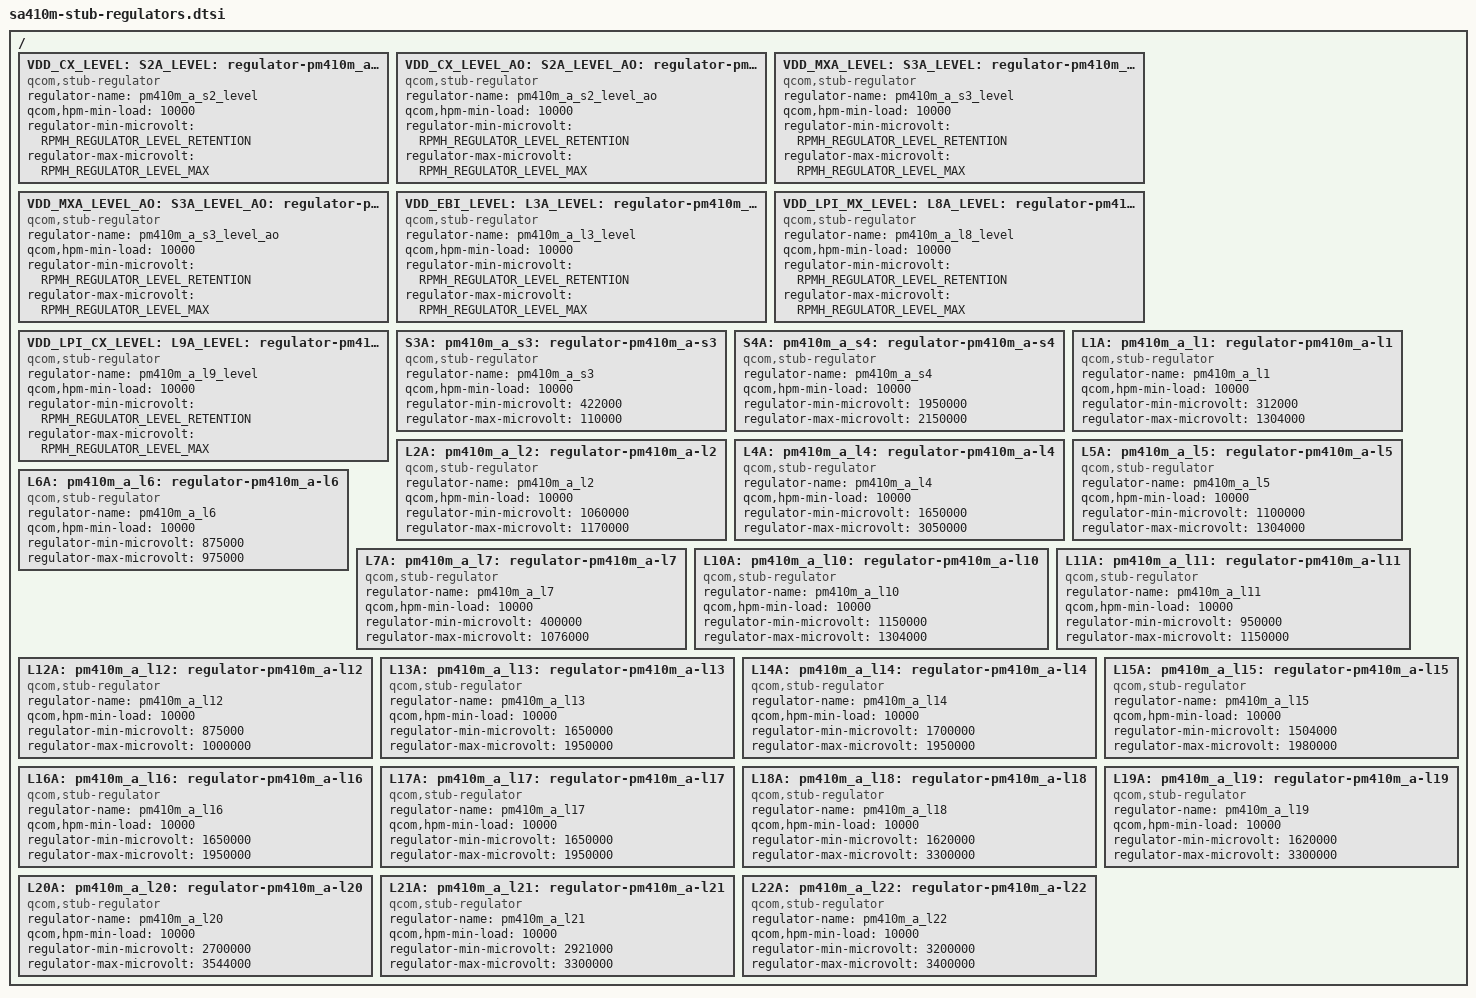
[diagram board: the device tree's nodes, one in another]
#include <dt-bindings/regulator/qcom,rpmh-regulator-levels.h>

/ {

	VDD_CX_LEVEL:
	S2A_LEVEL:
	pm410m_a_s2_level: regulator-pm410m_a-s2-level {
		compatible = "qcom,stub-regulator";
		regulator-name = "pm410m_a_s2_level";
		qcom,hpm-min-load = <10000>;
		regulator-min-microvolt =
			<RPMH_REGULATOR_LEVEL_RETENTION>;
		regulator-max-microvolt =
			<RPMH_REGULATOR_LEVEL_MAX>;
	};

	VDD_CX_LEVEL_AO:
	S2A_LEVEL_AO:
	pm410m_a_s2_level_ao: regulator-pm410m_a-s2-level-ao {
		compatible = "qcom,stub-regulator";
		regulator-name = "pm410m_a_s2_level_ao";
		qcom,hpm-min-load = <10000>;
		regulator-min-microvolt =
			<RPMH_REGULATOR_LEVEL_RETENTION>;
		regulator-max-microvolt =
			<RPMH_REGULATOR_LEVEL_MAX>;
	};

	VDD_MXA_LEVEL:
	S3A_LEVEL:
	pm410m_a_s3_level: regulator-pm410m_a-s3-level {
		compatible = "qcom,stub-regulator";
		regulator-name = "pm410m_a_s3_level";
		qcom,hpm-min-load = <10000>;
		regulator-min-microvolt =
			<RPMH_REGULATOR_LEVEL_RETENTION>;
		regulator-max-microvolt =
			<RPMH_REGULATOR_LEVEL_MAX>;
	};

	VDD_MXA_LEVEL_AO:
	S3A_LEVEL_AO:
	pm410m_a_s3_level_ao: regulator-pm410m_a-s3-level-ao {
		compatible = "qcom,stub-regulator";
		regulator-name = "pm410m_a_s3_level_ao";
		qcom,hpm-min-load = <10000>;
		regulator-min-microvolt =
			<RPMH_REGULATOR_LEVEL_RETENTION>;
		regulator-max-microvolt =
			<RPMH_REGULATOR_LEVEL_MAX>;
	};

	VDD_EBI_LEVEL:
	L3A_LEVEL:
	pm410m_a_l3_level: regulator-pm410m_a-l3-level {
		compatible = "qcom,stub-regulator";
		regulator-name = "pm410m_a_l3_level";
		qcom,hpm-min-load = <10000>;
		regulator-min-microvolt =
			<RPMH_REGULATOR_LEVEL_RETENTION>;
		regulator-max-microvolt =
			<RPMH_REGULATOR_LEVEL_MAX>;
	};

	VDD_LPI_MX_LEVEL:
	L8A_LEVEL:
	pm410m_a_l8_level: regulator-pm410m_a-l8-level {
		compatible = "qcom,stub-regulator";
		regulator-name = "pm410m_a_l8_level";
		qcom,hpm-min-load = <10000>;
		regulator-min-microvolt =
			<RPMH_REGULATOR_LEVEL_RETENTION>;
		regulator-max-microvolt =
			<RPMH_REGULATOR_LEVEL_MAX>;
	};

	VDD_LPI_CX_LEVEL:
	L9A_LEVEL:
	pm410m_a_l9_level: regulator-pm410m_a-l9-level {
		compatible = "qcom,stub-regulator";
		regulator-name = "pm410m_a_l9_level";
		qcom,hpm-min-load = <10000>;
		regulator-min-microvolt =
			<RPMH_REGULATOR_LEVEL_RETENTION>;
		regulator-max-microvolt =
			<RPMH_REGULATOR_LEVEL_MAX>;
	};

	S3A:
	pm410m_a_s3: regulator-pm410m_a-s3 {
		compatible = "qcom,stub-regulator";
		regulator-name = "pm410m_a_s3";
		qcom,hpm-min-load = <10000>;
		regulator-min-microvolt = <422000>;
		regulator-max-microvolt = <110000>;
	};

	S4A:
	pm410m_a_s4: regulator-pm410m_a-s4 {
		compatible = "qcom,stub-regulator";
		regulator-name = "pm410m_a_s4";
		qcom,hpm-min-load = <10000>;
		regulator-min-microvolt = <1950000>;
		regulator-max-microvolt = <2150000>;
	};

	L1A:
	pm410m_a_l1: regulator-pm410m_a-l1 {
		compatible = "qcom,stub-regulator";
		regulator-name = "pm410m_a_l1";
		qcom,hpm-min-load = <10000>;
		regulator-min-microvolt = <312000>;
		regulator-max-microvolt = <1304000>;
	};

	L2A:
	pm410m_a_l2: regulator-pm410m_a-l2 {
		compatible = "qcom,stub-regulator";
		regulator-name = "pm410m_a_l2";
		qcom,hpm-min-load = <10000>;
		regulator-min-microvolt = <1060000>;
		regulator-max-microvolt = <1170000>;
	};

	L4A:
	pm410m_a_l4: regulator-pm410m_a-l4 {
		compatible = "qcom,stub-regulator";
		regulator-name = "pm410m_a_l4";
		qcom,hpm-min-load = <10000>;
		regulator-min-microvolt = <1650000>;
		regulator-max-microvolt = <3050000>;
	};

	L5A:
	pm410m_a_l5: regulator-pm410m_a-l5 {
		compatible = "qcom,stub-regulator";
		regulator-name = "pm410m_a_l5";
		qcom,hpm-min-load = <10000>;
		regulator-min-microvolt = <1100000>;
		regulator-max-microvolt = <1304000>;
	};

	L6A:
	pm410m_a_l6: regulator-pm410m_a-l6 {
		compatible = "qcom,stub-regulator";
		regulator-name = "pm410m_a_l6";
		qcom,hpm-min-load = <10000>;
		regulator-min-microvolt = <875000>;
		regulator-max-microvolt = <975000>;
	};

	L7A:
	pm410m_a_l7: regulator-pm410m_a-l7 {
		compatible = "qcom,stub-regulator";
		regulator-name = "pm410m_a_l7";
		qcom,hpm-min-load = <10000>;
		regulator-min-microvolt = <400000>;
		regulator-max-microvolt = <1076000>;
	};

	L10A:
	pm410m_a_l10: regulator-pm410m_a-l10 {
		compatible = "qcom,stub-regulator";
		regulator-name = "pm410m_a_l10";
		qcom,hpm-min-load = <10000>;
		regulator-min-microvolt = <1150000>;
		regulator-max-microvolt = <1304000>;
	};

	L11A:
	pm410m_a_l11: regulator-pm410m_a-l11 {
		compatible = "qcom,stub-regulator";
		regulator-name = "pm410m_a_l11";
		qcom,hpm-min-load = <10000>;
		regulator-min-microvolt = <950000>;
		regulator-max-microvolt = <1150000>;
	};

	L12A:
	pm410m_a_l12: regulator-pm410m_a-l12 {
		compatible = "qcom,stub-regulator";
		regulator-name = "pm410m_a_l12";
		qcom,hpm-min-load = <10000>;
		regulator-min-microvolt = <875000>;
		regulator-max-microvolt = <1000000>;
	};

	L13A:
	pm410m_a_l13: regulator-pm410m_a-l13 {
		compatible = "qcom,stub-regulator";
		regulator-name = "pm410m_a_l13";
		qcom,hpm-min-load = <10000>;
		regulator-min-microvolt = <1650000>;
		regulator-max-microvolt = <1950000>;
	};

	L14A:
	pm410m_a_l14: regulator-pm410m_a-l14 {
		compatible = "qcom,stub-regulator";
		regulator-name = "pm410m_a_l14";
		qcom,hpm-min-load = <10000>;
		regulator-min-microvolt = <1700000>;
		regulator-max-microvolt = <1950000>;
	};

	L15A:
	pm410m_a_l15: regulator-pm410m_a-l15 {
		compatible = "qcom,stub-regulator";
		regulator-name = "pm410m_a_l15";
		qcom,hpm-min-load = <10000>;
		regulator-min-microvolt = <1504000>;
		regulator-max-microvolt = <1980000>;
	};

	L16A:
	pm410m_a_l16: regulator-pm410m_a-l16 {
		compatible = "qcom,stub-regulator";
		regulator-name = "pm410m_a_l16";
		qcom,hpm-min-load = <10000>;
		regulator-min-microvolt = <1650000>;
		regulator-max-microvolt = <1950000>;
	};

	L17A:
	pm410m_a_l17: regulator-pm410m_a-l17 {
		compatible = "qcom,stub-regulator";
		regulator-name = "pm410m_a_l17";
		qcom,hpm-min-load = <10000>;
		regulator-min-microvolt = <1650000>;
		regulator-max-microvolt = <1950000>;
	};

	L18A:
	pm410m_a_l18: regulator-pm410m_a-l18 {
		compatible = "qcom,stub-regulator";
		regulator-name = "pm410m_a_l18";
		qcom,hpm-min-load = <10000>;
		regulator-min-microvolt = <1620000>;
		regulator-max-microvolt = <3300000>;
	};

	L19A:
	pm410m_a_l19: regulator-pm410m_a-l19 {
		compatible = "qcom,stub-regulator";
		regulator-name = "pm410m_a_l19";
		qcom,hpm-min-load = <10000>;
		regulator-min-microvolt = <1620000>;
		regulator-max-microvolt = <3300000>;
	};

	L20A:
	pm410m_a_l20: regulator-pm410m_a-l20 {
		compatible = "qcom,stub-regulator";
		regulator-name = "pm410m_a_l20";
		qcom,hpm-min-load = <10000>;
		regulator-min-microvolt = <2700000>;
		regulator-max-microvolt = <3544000>;
	};

	L21A:
	pm410m_a_l21: regulator-pm410m_a-l21 {
		compatible = "qcom,stub-regulator";
		regulator-name = "pm410m_a_l21";
		qcom,hpm-min-load = <10000>;
		regulator-min-microvolt = <2921000>;
		regulator-max-microvolt = <3300000>;
	};

	L22A:
	pm410m_a_l22: regulator-pm410m_a-l22 {
		compatible = "qcom,stub-regulator";
		regulator-name = "pm410m_a_l22";
		qcom,hpm-min-load = <10000>;
		regulator-min-microvolt = <3200000>;
		regulator-max-microvolt = <3400000>;
	};
};
